# RZN2H register map
Vendor: Renesas Electronics Corporation; Series: RZN; File version: 1.00.00
CPU: other r0p0, little endian, MPU, no FPU, VTOR, 4 interrupt priority bits, 624 interrupts
Registers are 32-bit, read-write, reset 0x0 unless marked. A register's access mark holds for its fields unless they carry their own. Offsets are from the block's base; [hi:lo] are bit positions; {n}, {i} and the like mark numbered series.

## ETHSS — Ethernet Subsystem
Base 0x80110000
0x00 PRCMD — Ethernet Protect Register
0x08 MODCTRL — Mode Control Register
  [2:0] SW_MODE — Selects the function of the Media interface of the MAC to be used
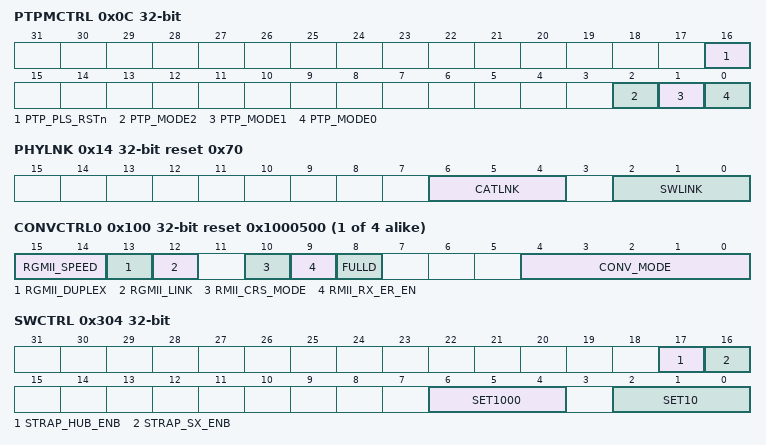
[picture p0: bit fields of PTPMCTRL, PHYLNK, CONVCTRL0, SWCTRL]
0x0C PTPMCTRL — PTP Mode Control Register
  [16] PTP_PLS_RSTn — Reset control for Pulse Generator (unit 0 - 3)
    0=Assert RESET; 1=Release RESET
  [2] PTP_MODE2 — Select the unit number of PTP Timer for GMAC2
    0=Ethernet Switch Timer 0; 1=Ethernet Switch Timer 1
  [1] PTP_MODE1 — Select the unit number of PTP Timer for GMAC1
    0=Ethernet Switch Timer 0; 1=Ethernet Switch Timer 1
  [0] PTP_MODE0 — Select the unit number of PTP Timer for GMAC0 and Pulse Generator (unit 0 - 3)
    0=Ethernet Switch Timer 0; 1=Ethernet Switch Timer 1
0x14 PHYLNK reset 0x70 — Ethernet PHY Link Mode Register
  [6:4] CATLNK — Specify the active level of the ESC_PHYLINKn signal using the EtherCAT interface
    0=Active-Low PHYLINK signal; 1=Active-High PHYLINK signal
  [2:0] SWLINK — Specify the active level of the ETHSW_PHYLINKn signal using the Ethernet switch interface
    0=Active-High PHYLINK signal; 1=Active-Low PHYLINK signal
{0x100+4i} CONVCTRL{i} (i=0..3) reset 0x1000500 — RGMII/RMII Converter {i} Control Register
  [15:14] RGMII_SPEED ro
    0=2.5 MHz; 1=25 MHz; 2=125 MHz
  [13] RGMII_DUPLEX ro
    0=Half-duplex; 1=Full-duplex
  [12] RGMII_LINK ro
    0=Down; 1=Up
  [10] RMII_CRS_MODE
    0=CRS | TX_EN; 1=CRS | TX_EN | RX_DV
  [9] RMII_RX_ER_EN
    0=RX_ER is always 0; 1=RX_ER signal
  [8] FULLD
    0=Half-duplex; 1=Full-duplex
  [4:0] CONV_MODE — Converter operation mode
0x114 CONVRST — RGMII/RMII Converter Reset Control Register
  [3:0] PHYIR
    0=Reset RGMII/RMII Converter; 1=Activate RGMII/RMII Converter
0x304 SWCTRL — Switch Core Control Register
  [17] STRAP_HUB_ENB — Initialize switch port 0 and 1 (set during module reset of ETHSW)
    0=Port 0 and 1 stay uninitialized; 1=Port 0 and 1 initialized
  [16] STRAP_SX_ENB — Initialize switch after reset (set during module reset of ETHSW)
    0=Switch stay uninitialized; 1=Switch initialized (line port)
  [6:4] SET1000 — Port control to select use of 1000 Mbps. Bit 0 = port 0, bit 1 = port 1, bit 2 = port 2.
    0=Not 1000 Mbps; 1=1000 Mbps
  [2:0] SET10 — Port control to select use of 10 Mbps. Bit 0 = port 0, bit 1 = port 1, bit 2 = port 2.
    0=Not 10 Mbps; 1=10 Mbps
0x308 SWDUPC — Switch Core Duplex Mode Register
  [2:0] PHY_DUPLEX — Configure the MAC of each port for full-duplex or half-duplex operation. Bit 0 = port 0, bit 1 = port 1, bit 2 = port 2.
    0=Half-duplex; 1=Full-duplex

## ESC_INI — Initial Configuration 1 for EtherCAT Slave Controller
Base 0x80110200
0x00 ECATOFFADR — EtherCAT PHY Offset Address Setting Register
  [4:0] OADD — PHY Offset Address Setting
0x04 ECATOPMOD — EtherCAT Operation Mode Register
  [0] EEPROMSIZE — EEPROM Memory Size Specification
    0=16 Kbits or less; 1=32 Kbits to 4 Mbits
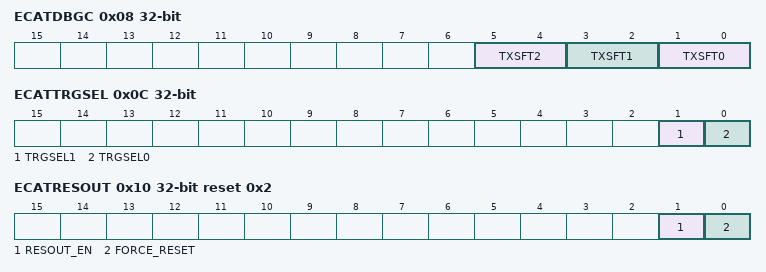
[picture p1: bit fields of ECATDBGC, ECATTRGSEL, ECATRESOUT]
0x08 ECATDBGC — EtherCAT Debug Control Register
  [all] fields
    0=0 ns; 1=10 ns; 2=20 ns; 3=30 ns
  [5:4] TXSFT2 — Set the delay time for ETH2_TXEN and ETH2_TXDn of the EtherCAT
  [3:2] TXSFT1 — Set the delay time for ETH1_TXEN and ETH1_TXDn of the EtherCAT
  [1:0] TXSFT0 — Set the delay time for ETH0_TXEN and ETH0_TXDn of the EtherCAT
0x0C ECATTRGSEL — EtherCAT DC Latch Trigger Select Register
  [1] TRGSEL1 — Select DC Latch Trigger 1 for ESC
    0=Select LATCH1 input from ELC; 1=Select LATCH1 input from external
  [0] TRGSEL0 — Select DC Latch Trigger 0 for ESC
    0=Select LATCH0 input from ELC; 1=Select LATCH0 input from external
0x10 ECATRESOUT reset 0x2 — EtherCAT Reset Out Control register
  [1] RESOUT_EN
    0=Reset out from ESC is not output to ESC_RESETOUT# pin; 1=Reset out from ESC is output to ESC_RESETOUT# pin
  [0] FORCE_RESET
    0=Do not force reset state; 1=Force reset state (Low level output)
